# STM32N655 register map
File version: 1.0
CPU: CM55 r0p1, little endian, no MPU, FPU, vendor SysTick, 8 interrupt priority bits
Registers are 32-bit, read-write, reset 0x0 unless marked. A register's access mark holds for its fields unless they carry their own. Offsets are from the block's base; [hi:lo] are bit positions; {n}, {i} and the like mark numbered series; 'fields as' and 'values as' point back to an identical list.

## MCE1 — Memory cipher engine
Base 0x4802B800
Same registers: MCE2 0x4802BC00, MCE3 0x4802C000, MCE4 0x4802E000, MCE1_S 0x5802B800, MCE2_S 0x5802BC00, MCE3_S 0x5802C000, MCE4_S 0x5802E000
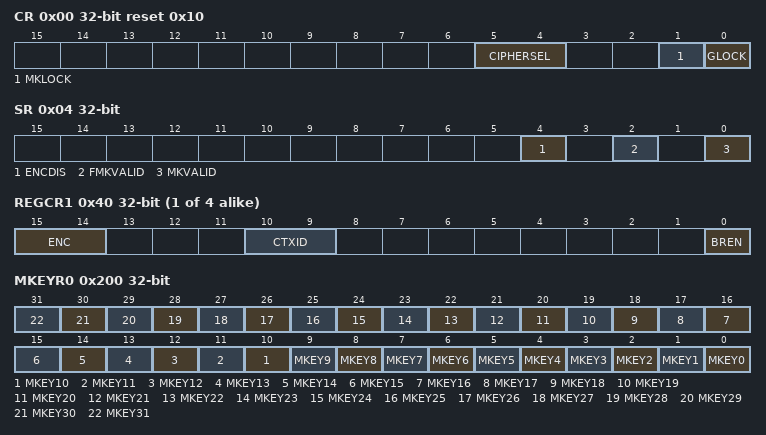
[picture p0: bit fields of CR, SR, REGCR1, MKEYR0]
0x00 CR reset 0x10 — MCE configuration register
  [5:4] CIPHERSEL — Cipher selection
  [1] MKLOCK — Master keys lock
  [0] GLOCK — Global lock
0x04 SR ro — MCE status register
  [4] ENCDIS — encryption disabled
  [2] FMKVALID — Fast master key valid
  [0] MKVALID — Master key valid
0x08 IASR ro — MCE illegal access status register
  [1] IAEF — Illegal access error flag
0x0C IACR wo — MCE illegal access clear register
  [1] IAEF — Illegal access error flag clear
0x10 IAIER ro — MCE illegal access interrupt enable register
  [1] IAEIE — Illegal access error interrupt enable
0x24 IADDR ro — MCE illegal address register
  [31:0] IADD — Illegal address
{0x30+0x10*i} REGCR{i} (i=1..4) — MCE region {i} configuration register
  [15:14] ENC — Encrypted region
  [10:9] CTXID — Context ID
  [0] BREN — Base region enable
{0x34+0x10*i} SADDR{i} (i=1..4) — MCE start address for region {i} register
  [31:12] BADDSTART — Region address start
{0x38+0x10*i} EADDR{i} reset 0xFFF (i=1..4) — MCE end address for region {i} register
  [31:12] BADDEND — Region address end
0x200 MKEYR0 wo — .MCE master key 0
  [n] MKEY{n} (n=0..31) — Master key bit {n} (i = 31 to 0)
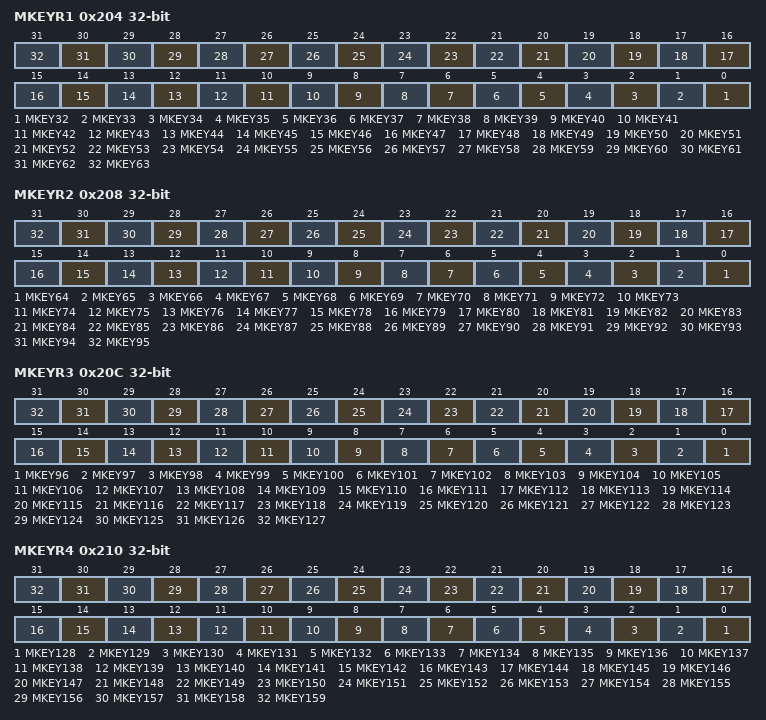
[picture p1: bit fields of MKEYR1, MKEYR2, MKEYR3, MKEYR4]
0x204 MKEYR1 wo — .MCE master key 1
  [n-32] MKEY{n} (n=32..63) — Master key bit {n} (i = 31 to 0)
0x208 MKEYR2 wo — .MCE master key 2
  [n-64] MKEY{n} (n=64..95) — Master key bit {n} (i = 31 to 0)
0x20C MKEYR3 wo — .MCE master key 3
  [n-96] MKEY{n} (n=96..127) — Master key bit {n} (i = 31 to 0)
0x210 MKEYR4 wo — .MCE master key 4
  [n-128] MKEY{n} (n=128..159) — Master key bit {n} (i = 31 to 0)
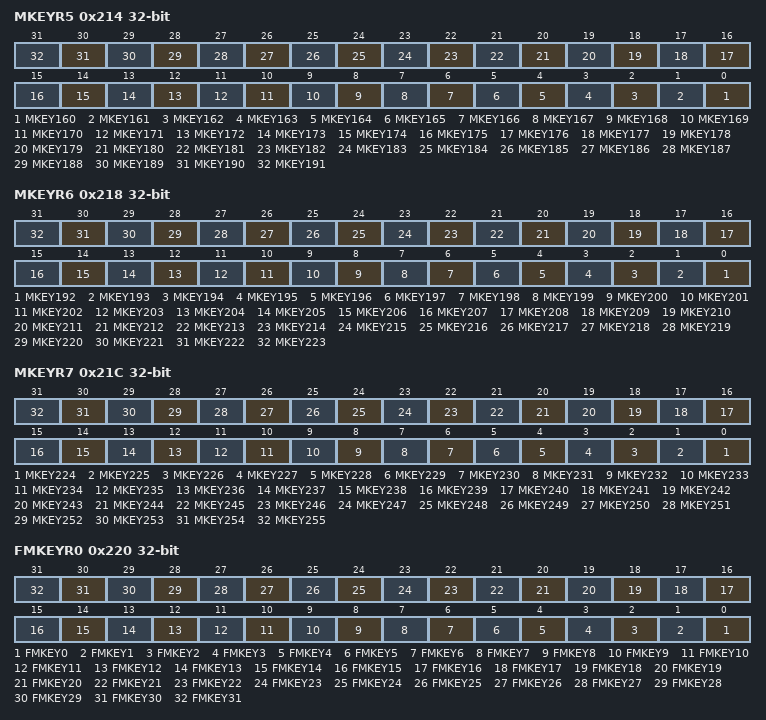
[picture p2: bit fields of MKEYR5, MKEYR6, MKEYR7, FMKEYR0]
0x214 MKEYR5 wo — .MCE master key 5
  [n-160] MKEY{n} (n=160..191) — Master key bit {n} (i = 31 to 0)
0x218 MKEYR6 wo — .MCE master key 6
  [n-192] MKEY{n} (n=192..223) — Master key bit {n} (i = 31 to 0)
0x21C MKEYR7 wo — .MCE master key 7
  [n-224] MKEY{n} (n=224..255) — Master key bit {n} (i = 31 to 0)
0x220 FMKEYR0 wo — MCE fast master key 0
  [n] FMKEY{n} (n=0..31) — Fast master key bit {n} (i = 31 to 0)
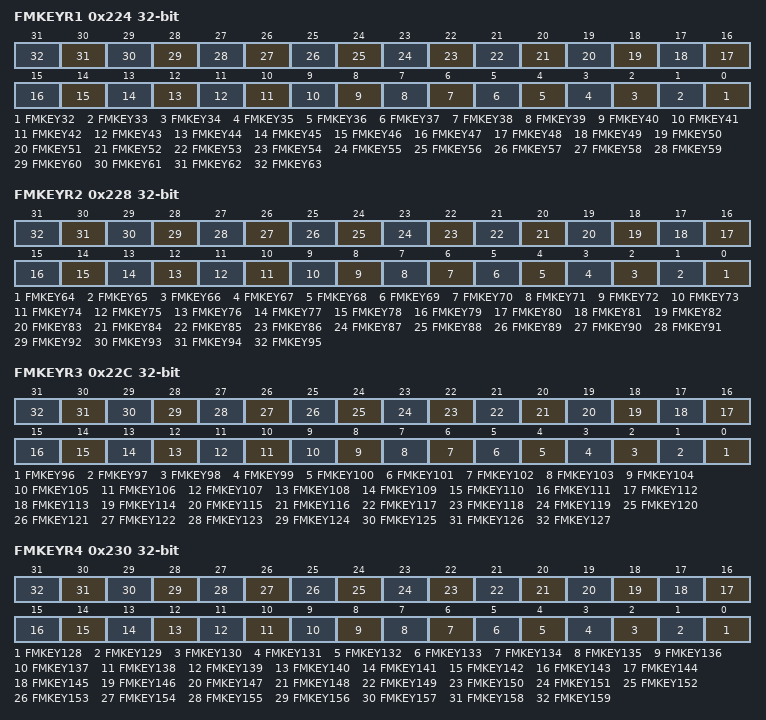
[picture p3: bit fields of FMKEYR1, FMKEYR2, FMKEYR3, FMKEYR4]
0x224 FMKEYR1 wo — MCE fast master key 1
  [n-32] FMKEY{n} (n=32..63) — Fast master key bit {n} (i = 31 to 0)
0x228 FMKEYR2 wo — MCE fast master key 2
  [n-64] FMKEY{n} (n=64..95) — Fast master key bit {n} (i = 31 to 0)
0x22C FMKEYR3 wo — MCE fast master key 3
  [n-96] FMKEY{n} (n=96..127) — Fast master key bit {n} (i = 31 to 0)
0x230 FMKEYR4 wo — MCE fast master key 4
  [n-128] FMKEY{n} (n=128..159) — Fast master key bit {n} (i = 31 to 0)
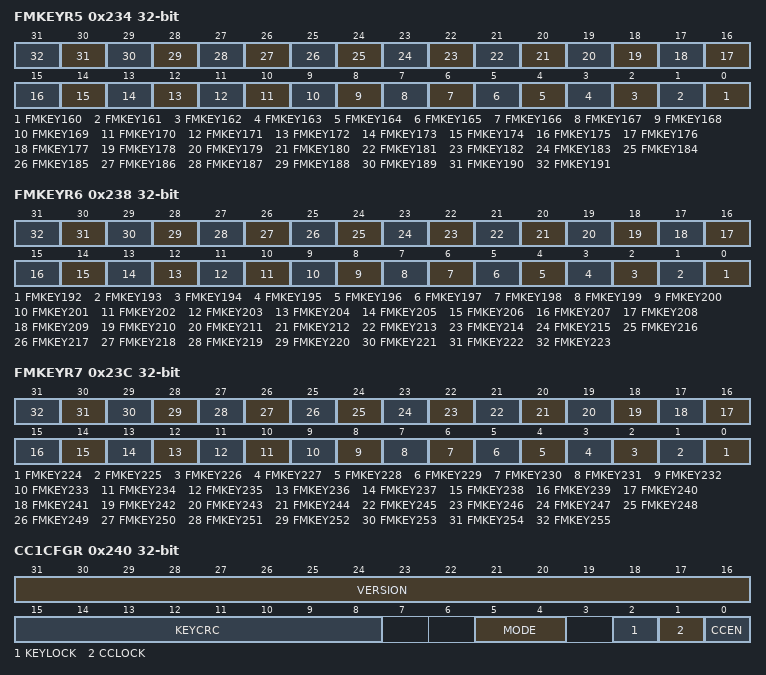
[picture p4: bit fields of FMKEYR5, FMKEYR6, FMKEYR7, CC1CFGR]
0x234 FMKEYR5 wo — MCE fast master key 5
  [n-160] FMKEY{n} (n=160..191) — Fast master key bit {n} (i = 31 to 0)
0x238 FMKEYR6 wo — MCE fast master key 6
  [n-192] FMKEY{n} (n=192..223) — Fast master key bit {n} (i = 31 to 0)
0x23C FMKEYR7 wo — MCE fast master key 7
  [n-224] FMKEY{n} (n=224..255) — Fast master key bit {n} (i = 31 to 0)
0x240 CC1CFGR access per field — MCE cipher context 1 configuration register
  [31:16] VERSION rw
  [15:8] KEYCRC ro
  [5:4] MODE rw — Authorized cipher mode
  [2] KEYLOCK rw
  [1] CCLOCK rw — Cipher context lock
  [0] CCEN rw — Cipher context enable
0x244 CC1NR0 — MCE cipher context 1 nonce register 0
  [31:0] SCNONCE — Stream cipher nonce, bits [31:0]
0x248 CC1NR1 — MCE cipher context 1 nonce register 1
  [31:0] SCNONCE — Stream cipher nonce, bits [63:32]
{0x24C+4i} CC1KEYR{i} wo (i=0..3) — MCE cipher context 1 key register {i}
  [31:0] KEY — cipher key, bits [{32i+31}:{32i}]
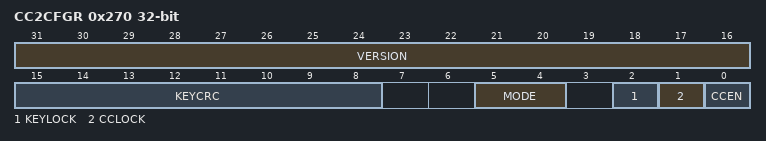
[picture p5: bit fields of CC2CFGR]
0x270 CC2CFGR access per field — MCE cipher context 2 configuration register
  fields as CC1CFGR
0x274 CC2NR0 — MCE cipher context 2 nonce register 0
  [31:0] SCNONCE — Stream cipher nonce, bits [31:0]
0x278 CC2NR1 — MCE cipher context 2 nonce register 1
  [31:0] SCNONCE — Stream cipher nonce, bits [63:32]
{0x27C+4i} CC2KEYR{i} wo (i=0..3) — MCE cipher context 2 key register {i}
  [31:0] KEY — cipher key, bits [{32i+31}:{32i}]
